# DSI1_PLLCTRL_L4_PER register map
Vendor: Texas Instruments
Peripheral module from a debugger description file (folder omap4460).
Registers are 32-bit, access per field, reset 0x0 unless marked. A register's access mark holds for its fields unless they carry their own. Offsets are as the file gives them; lines under a group give offsets from that group; [hi:lo] are bit positions; {n}, {i} and the like mark numbered series; 'fields as' and 'values as' point back to an identical list; <NAME> marks a mode.

## DSI1_PLLCTRL_L4_PER
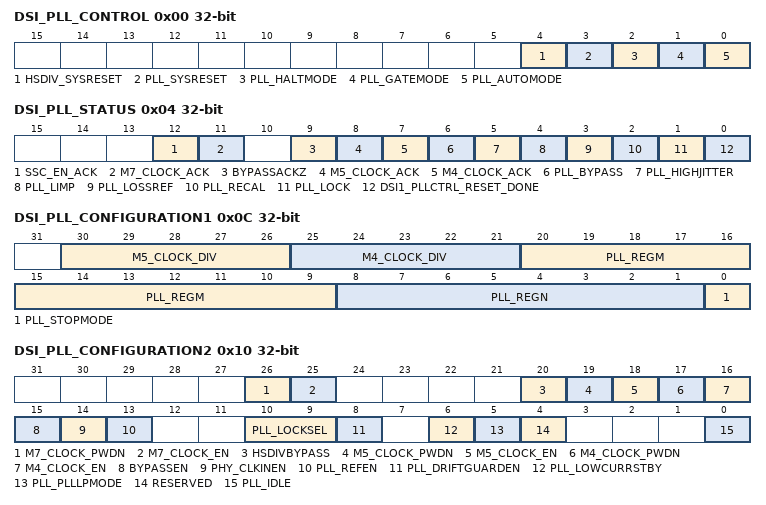
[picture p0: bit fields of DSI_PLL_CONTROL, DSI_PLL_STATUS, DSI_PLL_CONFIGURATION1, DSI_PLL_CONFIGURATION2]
0x00 DSI_PLL_CONTROL — This register controls the PLL reset/power and modes
  [4] HSDIV_SYSRESET rw — Force HSDIVIDER SYSRESET
    0=HSDIVIDER SYSRESET controlled by power FSM; 1=HSDIVIDER SYSRESET forced active
  [3] PLL_SYSRESET rw — Force DSI PLL SYSRESET
    0=PLL SYSRESET controlled by power FSM; 1=PLL SYSRESET forced active
  [2] PLL_HALTMODE rw — Allow PLL to be halted if no activity. Reserved when DSI1_PLLCTRL_AUTO is 0.
    0=PLL will not be halted; 1=PLL will be halted based on activity
  [1] PLL_GATEMODE rw — Allow PLL clock gating for power saving Reserved when DSI1_PLLCTRL_AUTO is 0.
    0=CLKIN4DDR clock on; 1=CLKIN4DDR clock gated by DSI Protocol Engine activity
  [0] PLL_AUTOMODE rw — Automatic update mode. If this bit is set then the configuration updates will be synchronised to DISPCUpdateSync. If this bit is clear configuration updates will be done immediately. Reserved when DSI1_PLLCTRL_AUTO is 0.
    0=Manual mode; 1=Automatic mode
0x04 DSI_PLL_STATUS ro — This register contains the status information
  [12] SSC_EN_ACK — Spread Spectrum Clocking acknowledge
    0=SSC_EN_ACK_0_r (Spread Spectrum Clocking inactive); 1=SSC_EN_ACK_1_r (Spread Spectrum Clocking active)
  [11] M7_CLOCK_ACK — Acknowledge for enable of clock Verify the status before selecting this source in the clock mux
    0=M7_CLOCK_ACK_0_r (M7 clock inactive); 1=M7_CLOCK_ACK_1_r (M7 clock active)
  [9] BYPASSACKZ — State of bypass mode on PHY and HSDIVIDER
    0=BYPASSACKZ_0_r (DSI_PHY and HSDIVIDER have switched to using the bypass clocks.); 1=BYPASSACKZ_1_r (PLL outputs are still being used by DSI_PHY or HSDIVIDER)
  [8] M5_CLOCK_ACK — Acknowledge for enable of DSI Protcol Engine clock Verify the status before selecting this source in the DSI Protcol Engine clock mux
    0=M5_CLOCK_ACK_0_r (M5 Protocol Engine clock inactive); 1=M5_CLOCK_ACK_1_r (M5 Protocol Engine clock active)
  [7] M4_CLOCK_ACK — Acknowledge for enable of clock Verify the status before selecting this source in the clock mux
    0=M4_CLOCK_ACK_0_r (M4 clock inactive); 1=M4_CLOCK_ACK_1_r (M4 clock active)
  [6] PLL_BYPASS — DSI PLL Bypass status
    0=PLL_BYPASS_0_r (PLL not bypassing); 1=PLL_BYPASS_1_r
  [5] PLL_HIGHJITTER — PLL High Jitter status
    0=PLL_HIGHJITTER_0_r (PLL in normal jitter condition); 1=PLL_HIGHJITTER_1_r (PLL in high jitter condition: Phase error > 24%)
  [4] PLL_LIMP — PLL Limp status
    0=PLL_LIMP_0_r (LIMP mode inactive); 1=PLL_LIMP_1_r (LIMP mode active)
  [3] PLL_LOSSREF — PLL Reference Loss status
    0=PLL_LOSSREF_0_r (Reference input active); 1=PLL_LOSSREF_1_r (Reference input inactive)
  [2] PLL_RECAL — PLL recalibration status If this bit is active, the PLL needs to be recalibrated
    0=PLL_RECAL_0_r (Recalibration is not required); 1=PLL_RECAL_1_r (Recalibration is required)
  [1] PLL_LOCK — PLL Lock status See the programming guide for the use of this bit
    0=PLL_LOCK_0_r (PLL is not locked); 1=PLL_LOCK_1_r (PLL is locked)
  [0] DSI1_PLLCTRL_RESET_DONE — DSI1_PLLCTRL reset done status
    0=DSI1_PLLCTRL_RESET_DONE_0_r (Reset is in progress); 1=DSI1_PLLCTRL_RESET_DONE_1_r (Reset has completed)
0x08 DSI_PLL_GO — This register contains the GO bit
  [0] PLL_GO rw — Request (re-)locking sequence of the PLL. If the AutoMode bit is set, then this will be deferred until DISPCUpdate Sync goes active
    0=No pending action; 1=Request PLL (re-)locking/locking pending
0x0C DSI_PLL_CONFIGURATION1 — This register contains the latched PLL and HSDIVDER configuration bits
  [30:26] M5_CLOCK_DIV rw — Divider value for Protocol Engine clock source M5REG
  [25:21] M4_CLOCK_DIV rw — Divider value for clock source M4REG
  [20:9] PLL_REGM rw — M Divider for PLL
  [8:1] PLL_REGN rw — N Divider for PLL (Reference)Note: As a result of device-specific integration, the 8th MSB of this field has no effect; thus, the divider factor can be 0 to 127. .
  [0] PLL_STOPMODE rw
    0=STOPMODE is not selected; 1=STOPMODE is selected
0x10 DSI_PLL_CONFIGURATION2 — This register contains the unlatched PLL and HSDIVDER configuration bits These bits are 'shadowed' when automatic mode is selected
  [26] M7_CLOCK_PWDN rw — Power down for M7 clock source
    0=M7 clock divider is active; 1=M7 clock divider is powered-down
  [25] M7_CLOCK_EN rw — Enable for M7 clock source
    0=M7 clock divider is disbled; 1=M7 clock divider is enabled
  [20] HSDIVBYPASS rw — Forces HSDIVIDER to bypass mode
    0=HSDIVIDER in normal operation. Bypass controlled by PLL.; 1=HSDIVIDER forced to bypass mode
  [19] M5_CLOCK_PWDN rw — Power down for Protocol Engine clock source
    0=DSI Protocol Engine clock divider is active; 1=DSI Protocol Engine clock divider is powered-down
  [18] M5_CLOCK_EN rw — Enable for Protocol Engine clock source
    0=DSI Protocol Engine clock divider is disabled; 1=DSI Protocol Engine clock divider is enabled
  [17] M4_CLOCK_PWDN rw — Power down for M4 clock source
    0=clock divider is active; 1=clock divider is powered-down
  [16] M4_CLOCK_EN rw — Enable for M4 clock source
    0=clock divider is disabled; 1=clock divider is enabled
  [15] BYPASSEN rw — Selects functional clock asCLKIN4DDR clock source
    0=PLL controls CLKIN4DDR clock source: PLL DCO if PLL is locked functional clock if not locked; 1=Force functional clock to be used as CLKIN4DDR clock source
  [14] PHY_CLKINEN rw — CLKIN4DDR clock control
    0=CLKIN4DDR clock is disabled; 1=CLKIN4DDR clock is enabled
  [13] PLL_REFEN rw — PLL reference clock control
    0=PLL reference clock disabled; 1=PLL reference clock enabled
  [10:9] PLL_LOCKSEL rw — Selects the lock criteria for the PLL
    0=Phase Lock; 1=Frequency Lock; 2=Spare
  [8] PLL_DRIFTGUARDEN rw
    0=Only RECAL flag is asserted in case of temperature drift. The programmer should take appropriate action.; 1=Temperature drift will initiate automatic recalibration. RECAL flag will be asserted while this is taking place.
  [6] PLL_LOWCURRSTBY rw — PLL LOW CURRENT STANDBY
    0=LOWCURRSTBY is not selected; 1=LOWCURRSTBY is selected
  [5] PLL_PLLLPMODE rw — Select the power / performance of the PLL
    0=Full performance, minimised jitter; 1=Reduced power, increased jitter
  [4] RESERVED ro — Reads return zero.
  [0] PLL_IDLE rw
    0=IDLE is not selected; 1=IDLE is selected
0x14 DSI_PLL_CONFIGURATION3 — HSDIVIDER configuration bits for the M5 and M6 dividers
  [9:5] M7_CLOCK_DIV rw — Divider value for M7 divider.
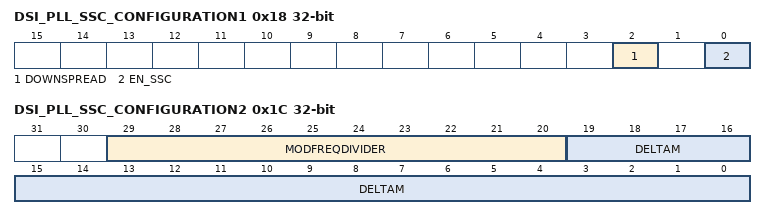
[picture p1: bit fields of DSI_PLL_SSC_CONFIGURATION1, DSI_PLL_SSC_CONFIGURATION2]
0x18 DSI_PLL_SSC_CONFIGURATION1 — Configuration for PLL Spread Spectrum Clocking modulation
  [2] DOWNSPREAD rw — Forces the clock spreading only in the down spectrum.
    0=Clock spreading not forced; 1=Spectrum spreading only in down direction
  [0] EN_SSC rw — Spread Spectrum Clockiing enable
    0=Spread Spectrum Clockiing disabled; 1=Spread Spectrum Clockiing enabled
0x1C DSI_PLL_SSC_CONFIGURATION2 — Configuration for PLL Spread Spectrum Clocking modulation
  [29:20] MODFREQDIVIDER rw — Modulation Frequency Divider (ModFreqDivider) control for SSCThe ModFreqDivider is split into Mantissa and 2Exponent(ModFreqDivider = ModFreqDividerMantissa * 2ModFreqDividerExponent). . Bits [29:23] define the Mantissa. . Bits [22:20] define the Exponent. .
  [19:0] DELTAM rw — DeltaM control for SSC. Split into integer and fractional parts.Bits [19:18] define the integer part. . Bits [17:0] define the fractional part. .
